AUTOSAR XML (schema 4-2-2)
package /Components
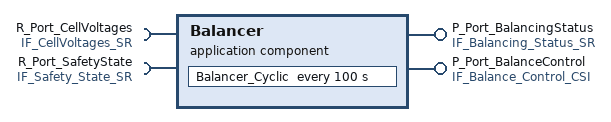
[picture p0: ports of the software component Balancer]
  application sw component type Balancer
    provide port P_Port_BalancingStatus: provided-interface=IF_Balancing_Status_SR
    provide port P_Port_BalanceControl: provided-interface=IF_Balance_Control_CSI
    require port R_Port_CellVoltages: required-interface=IF_CellVoltages_SR
    require port R_Port_SafetyState: required-interface=IF_Safety_State_SR
    behavior Balancer_InternalBehavior
      init event Balancer_Init_Event: start-on-event=Balancer_Init
      operation invoked event Balance_Enable_Invoked: start-on-event=Balancer_Handle_Enable
      operation invoked event Balance_Suspend_Invoked: start-on-event=Balancer_Handle_Suspend
      timing event Balancer_100ms_Event: start-on-event=Balancer_Cyclic, period=100
      4 x runnable:
        Balancer_Init
          data-receive-point-by-arguments:
            access VA_Init_Arg_MaxDeltaVoltage: accessed-variable=P_Port_BalanceControl.MaxDeltaVoltage
          data-receive-point-by-values:
            access VA_Init_Read_SafetyState: accessed-variable=R_Port_SafetyState.SafetyState
          data-send-points:
            access VA_Init_Send_BalancingActive: accessed-variable=P_Port_BalancingStatus.BalancingActive
            access VA_Init_Send_MaxDeltaVoltage: accessed-variable=P_Port_BalancingStatus.MaxDeltaVoltage
            access VA_Init_Send_BalancingFault: accessed-variable=P_Port_BalancingStatus.BalancingFault
        Balancer_Cyclic: minimum-start-interval=100
          data-receive-point-by-arguments:
            access VA_Cyc_Arg_MaxDeltaVoltage: accessed-variable=P_Port_BalanceControl.MaxDeltaVoltage
          data-receive-point-by-values:
            access VA_Cyc_Read_CellVoltages_Array: accessed-variable=R_Port_CellVoltages.CellVoltages_Array
            access VA_Cyc_Read_SafetyState: accessed-variable=R_Port_SafetyState.SafetyState
          data-send-points:
            access VA_Cyc_Send_BalancingActive: accessed-variable=P_Port_BalancingStatus.BalancingActive
            access VA_Cyc_Send_MaxDeltaVoltage: accessed-variable=P_Port_BalancingStatus.MaxDeltaVoltage
            access VA_Cyc_Send_BalancingFault: accessed-variable=P_Port_BalancingStatus.BalancingFault
        Balancer_Handle_Enable
          data-receive-point-by-arguments:
            access VA_Enable_Arg_BalancingActive: accessed-variable=P_Port_BalanceControl.BalancingActive
          data-receive-point-by-values:
            access VA_Enable_Read_SafetyState: accessed-variable=R_Port_SafetyState.SafetyState
          data-send-points:
            access VA_Enable_Send_BalancingActive: accessed-variable=P_Port_BalancingStatus.BalancingActive
        Balancer_Handle_Suspend
          data-receive-point-by-arguments:
            access VA_Suspend_Arg_BalancingActive: accessed-variable=P_Port_BalanceControl.BalancingActive
          data-receive-point-by-values:
            access VA_Suspend_Read_FaultCode: accessed-variable=R_Port_SafetyState.FaultCode
          data-send-points:
            access VA_Suspend_Send_BalancingFault: accessed-variable=P_Port_BalancingStatus.BalancingFault
